# CCTEST register map
Vendor: Texas Instruments
Peripheral module from a debugger description file (folder cc2538).
Registers are 32-bit, access per field, no defined reset value unless marked. A register's access mark holds for its fields unless they carry their own. Offsets are as the file gives them; lines under a group give offsets from that group; [hi:lo] are bit positions; {n}, {i} and the like mark numbered series; 'fields as' and 'values as' point back to an identical list; <NAME> marks a mode.

## CCTEST — Register fields should be considered static unless otherwise noted as dynamic.
0x00 IO — Output strength control
  [0] SC rw — I/O strength control bit Common to all digital output pads Should be set when unregulated voltage is below approximately 2.6 V.
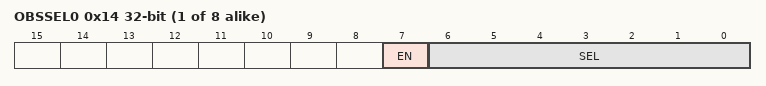
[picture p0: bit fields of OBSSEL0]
{0x14+4i} OBSSEL{i} (i=0..7) — Select output signal on observation output {i}
  [7] EN rw — Observation output {i} enable control for PC{i} 0: Observation output disabled 1: Observation output enabled Note: If enabled, this overwrites the standard GPIO behavior of PC{i}.
  [6:0] SEL rw — n - obs_sigs[n] output on output {i}: 0: rfc_obs_sig0 1: rfc_obs_sig1 2: rfc_obs_sig2 Others: Reserved
0x34 TR0 — Test register 0
  [1] ADCTM rw — Set to 1 to connect the temperature sensor to the SOC_ADC. See also RFCORE_XREG_ATEST register description to enable the temperature sensor.
0x50 USBCTRL — USB PHY stand-by control
  [0] USB_STB rw — USB PHY stand-by override bit When this bit is cleared to 0 (default state) the USB module cannot change the stand-by mode of the PHY (USB pads) and the PHY is forced out of stand-by mode. This bit must be 1 as well as the stand-by control from the USB controller, before the mode of the PHY is stand-by.
